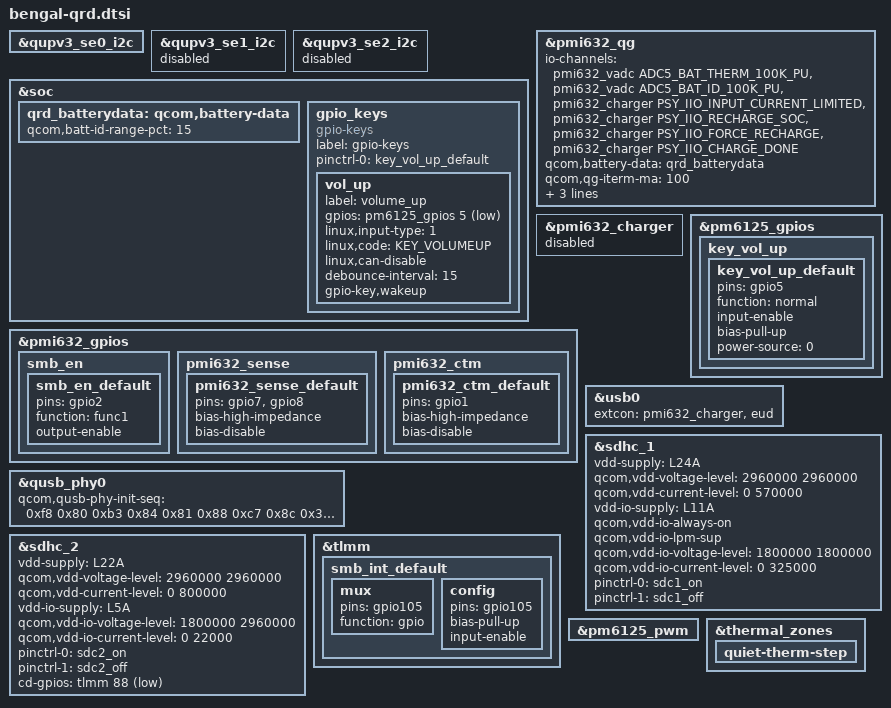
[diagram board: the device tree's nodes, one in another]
#include <dt-bindings/gpio/gpio.h>
#include <dt-bindings/iio/qcom,spmi-vadc.h>
#include <dt-bindings/input/input.h>
#include <dt-bindings/iio/qti_power_supply_iio.h>

&qupv3_se0_i2c {
	status = "ok";
};

&qupv3_se1_i2c {
	status = "disabled";
};

&qupv3_se2_i2c {
	status = "disabled";
};

&soc {
	qrd_batterydata: qcom,battery-data {
		qcom,batt-id-range-pct = <15>;
		#include "qg-batterydata-alium-3600mah.dtsi"
	};
};

&pmi632_qg {
	status = "ok";
	#io-channel-cells = <1>;
	io-channels = <&pmi632_vadc ADC5_BAT_THERM_100K_PU>,
			<&pmi632_vadc ADC5_BAT_ID_100K_PU>,
			<&pmi632_charger PSY_IIO_INPUT_CURRENT_LIMITED>,
			<&pmi632_charger PSY_IIO_RECHARGE_SOC>,
			<&pmi632_charger PSY_IIO_FORCE_RECHARGE>,
			<&pmi632_charger PSY_IIO_CHARGE_DONE>;
	io-channel-names = "batt-therm",
			   "batt-id",
			   "input_current_limited",
			   "recharge_soc",
			   "force_recharge",
			   "charge_done",
			   "cp_charging_enabled";
	qcom,battery-data = <&qrd_batterydata>;
	qcom,qg-iterm-ma = <100>;
	qcom,hold-soc-while-full;
	qcom,linearize-soc;
	qcom,qg-use-s7-ocv;
};

&pmi632_charger {
	status = "disabled";
};

&pmi632_gpios {
	smb_en {
		smb_en_default: smb_en_default {
			pins = "gpio2";
			function = "func1";
			output-enable;
		};
	};

	pmi632_sense {
		/* GPIO 7 and 8 are external-sense pins for PMI632 */
		pmi632_sense_default: pmi632_sense_default {
			pins = "gpio7", "gpio8";
			bias-high-impedance;	/* disable the GPIO */
			bias-disable;		/* no-pull */
		};
	};

	pmi632_ctm {
		/* Disable GPIO1 for h/w base mitigation */
		pmi632_ctm_default: pmi632_ctm_default {
			pins = "gpio1";
			bias-high-impedance;	/* disable the GPIO */
			bias-disable;		/* no-pull */
		};
	};
};

&pm6125_gpios {
	key_vol_up {
		key_vol_up_default: key_vol_up_default {
			pins = "gpio5";
			function = "normal";
			input-enable;
			bias-pull-up;
			power-source = <0>;
		};
	};
};

&usb0 {
	extcon = <&pmi632_charger>, <&eud>;
};

&qusb_phy0 {
	qcom,qusb-phy-init-seq = <0xf8 0x80
				0xb3 0x84
				0x81 0x88
				0xc7 0x8c
				0x30 0x08
				0x79 0x0c
				0x21 0x10
				0x14 0x9c
				0x80 0x04
				0x9f 0x1c
				0x00 0x18>;
};

&soc {
	gpio_keys {
		compatible = "gpio-keys";
		label = "gpio-keys";

		pinctrl-names = "default";
		pinctrl-0 = <&key_vol_up_default>;

		vol_up {
			label = "volume_up";
			gpios = <&pm6125_gpios 5 GPIO_ACTIVE_LOW>;
			linux,input-type = <1>;
			linux,code = <KEY_VOLUMEUP>;
			linux,can-disable;
			debounce-interval = <15>;
			gpio-key,wakeup;
		};
	};
};

&sdhc_1 {
	vdd-supply = <&L24A>;
	qcom,vdd-voltage-level = <2960000 2960000>;
	qcom,vdd-current-level = <0 570000>;

	vdd-io-supply = <&L11A>;
	qcom,vdd-io-always-on;
	qcom,vdd-io-lpm-sup;
	qcom,vdd-io-voltage-level = <1800000 1800000>;
	qcom,vdd-io-current-level = <0 325000>;

	pinctrl-names = "default", "sleep";
	pinctrl-0 = <&sdc1_on>;
	pinctrl-1 = <&sdc1_off>;
	status = "ok";
};

&sdhc_2 {
	vdd-supply = <&L22A>;
	qcom,vdd-voltage-level = <2960000 2960000>;
	qcom,vdd-current-level = <0 800000>;

	vdd-io-supply = <&L5A>;
	qcom,vdd-io-voltage-level = <1800000 2960000>;
	qcom,vdd-io-current-level = <0 22000>;

	pinctrl-names = "default", "sleep";
	pinctrl-0 = <&sdc2_on>;
	pinctrl-1 = <&sdc2_off>;

	cd-gpios = <&tlmm 88 GPIO_ACTIVE_LOW>;

	status = "ok";
};

&tlmm {
	smb_int_default: smb_int_default {
		mux {
			pins = "gpio105";
			function = "gpio";
		};

		config {
			pins = "gpio105";
			bias-pull-up;
			input-enable;
		};
	};
};

&pm6125_pwm {
	status = "ok";
};

&thermal_zones {
	quiet-therm-step {
		status = "ok";
	};
};
